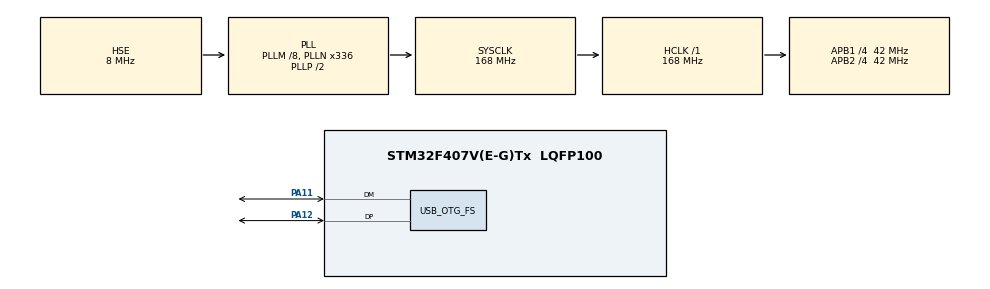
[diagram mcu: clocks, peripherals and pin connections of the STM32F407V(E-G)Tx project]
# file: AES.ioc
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Mcu.Family=STM32F4
Mcu.Name=STM32F407V(E-G)Tx
Mcu.Package=LQFP100
NVIC.OTG_FS_IRQn=true\:0\:0\:false\:false\:true
NVIC.PriorityGroup=NVIC_PRIORITYGROUP_4
PA11.Mode=Device_Only
PA11.Signal=USB_OTG_FS_DM
PA12.Mode=Device_Only
PA12.Signal=USB_OTG_FS_DP
PH0-OSC_IN.Mode=HSE-External-Oscillator
PH0-OSC_IN.Signal=RCC_OSC_IN
PH1-OSC_OUT.Mode=HSE-External-Oscillator
PH1-OSC_OUT.Signal=RCC_OSC_OUT
ProjectManager.HeapSize=0x200
ProjectManager.StackSize=0x400
ProjectManager.TargetToolchain=MDK-ARM V5
RCC.48MHZClocksFreq_Value=48000000
RCC.AHBFreq_Value=168000000
RCC.APB1CLKDivider=RCC_HCLK_DIV4
RCC.APB1Freq_Value=42000000
RCC.APB1TimFreq_Value=84000000
RCC.APB2CLKDivider=RCC_HCLK_DIV4
RCC.APB2Freq_Value=42000000
RCC.APB2TimFreq_Value=84000000
RCC.CortexFreq_Value=168000000
RCC.HCLKFreq_Value=168000000
RCC.HSE_VALUE=8000000
RCC.HSI_VALUE=16000000
RCC.LSE_VALUE=32768
RCC.PLLM=8
RCC.PLLN=336
RCC.PLLQ=7
RCC.SYSCLKFreq_VALUE=168000000
RCC.SYSCLKSource=RCC_SYSCLKSOURCE_PLLCLK
RCC.VCOOutputFreq_Value=336000000
USB_DEVICE.CLASS_NAME-CDC_FS=CDC
USB_DEVICE.CLASS_NAME_FS=CDC
USB_DEVICE.USBD_HandleTypeDef-CDC_FS=hUsbDeviceFS
USB_DEVICE.VirtualMode-CDC_FS=Cdc
USB_DEVICE.VirtualModeFS=Cdc_FS
USB_OTG_FS.VirtualMode=Device_Only
VP_USB_DEVICE_VS_USB_DEVICE_CDC_FS.Mode=CDC_FS
board=AES

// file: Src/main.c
/**
  ******************************************************************************
  * File Name          : main.c
  * Description        : Main program body
  ******************************************************************************
  *
  * COPYRIGHT(c) 2016 STMicroelectronics
  *
  * Redistribution and use in source and binary forms, with or without modification,
  * are permitted provided that the following conditions are met:
  *   1. Redistributions of source code must retain the above copyright notice,
  *      this list of conditions and the following disclaimer.
  *   2. Redistributions in binary form must reproduce the above copyright notice,
  *      this list of conditions and the following disclaimer in the documentation
  *      and/or other materials provided with the distribution.
  *   3. Neither the name of STMicroelectronics nor the names of its contributors
  *      may be used to endorse or promote products derived from this software
  *      without specific prior written permission.
  *
  * THIS SOFTWARE IS PROVIDED BY THE COPYRIGHT HOLDERS AND CONTRIBUTORS "AS IS"
  * AND ANY EXPRESS OR IMPLIED WARRANTIES, INCLUDING, BUT NOT LIMITED TO, THE
  * IMPLIED WARRANTIES OF MERCHANTABILITY AND FITNESS FOR A PARTICULAR PURPOSE ARE
  * DISCLAIMED. IN NO EVENT SHALL THE COPYRIGHT HOLDER OR CONTRIBUTORS BE LIABLE
  * FOR ANY DIRECT, INDIRECT, INCIDENTAL, SPECIAL, EXEMPLARY, OR CONSEQUENTIAL
  * DAMAGES (INCLUDING, BUT NOT LIMITED TO, PROCUREMENT OF SUBSTITUTE GOODS OR
  * SERVICES; LOSS OF USE, DATA, OR PROFITS; OR BUSINESS INTERRUPTION) HOWEVER
  * CAUSED AND ON ANY THEORY OF LIABILITY, WHETHER IN CONTRACT, STRICT LIABILITY,
  * OR TORT (INCLUDING NEGLIGENCE OR OTHERWISE) ARISING IN ANY WAY OUT OF THE USE
  * OF THIS SOFTWARE, EVEN IF ADVISED OF THE POSSIBILITY OF SUCH DAMAGE.
  *
  ******************************************************************************
  */
#include "stm32f4xx_hal.h"
#include "usb_device.h"

/* USER CODE BEGIN Includes */
#include "AES.h"
#include "usbd_cdc_if.h"

/* Mo ta hoat dong:
 * PC se gui xuong 17 byte, trong do byte dau tien chon che do
 * Neu byte dau tien = 0x11 thi chon mode ma hoa
 *                   = 0x22 thi chon mode giai ma
 * Tiep theo byte dau tien se la 16 byte du lieu
 * Tuy thuoc vao che do ma stm32f407 se dung 16 byte du lieu nay
 * de ma hoa hoac giai ma.
 * Sau do stm32 se gui len 17 byte. Trong do byte dau tien giong
 * byte ma may tinh gui xuong. 16 byte sau la du lieu da duoc ma hoa
 * hoac giai ma.
 */

/* USER CODE END Includes */

/* USER CODE BEGIN PV */
/* Private variables ---------------------------------------------------------*/
    AesCtx ctx;
    unsigned char i;
    unsigned char iv[] = "INI VECTINI VECT";
    unsigned char key[] = {0x00  ,0x01  ,0x02  ,0x03  ,0x04  ,0x05  ,0x06  ,0x07  ,0x08  ,0x09  ,0x0a  ,0x0b  ,0x0c  ,0x0d  ,0x0e  ,0x0f};
    unsigned char databuf[16]; // must be in multiple of 16
		unsigned char encryptbuf[16],decryptbuf[16];
    uint8_t _index=0;
		uint8_t receive_data[17];
		uint8_t send_data[17];
		uint8_t encrypt_flag=0,decrypt_flag=0;
/* USER CODE END PV */

void SystemClock_Config(void);
void Error_Handler(void);
static void MX_GPIO_Init(void);

/* USER CODE BEGIN PFP */
/* Private function prototypes -----------------------------------------------*/
void usb_cdc_isr(uint8_t * Buf);
/* USER CODE END PFP */

int main(void)
{

  /* MCU Configuration----------------------------------------------------------*/

  /* Reset of all peripherals, Initializes the Flash interface and the Systick. */
  HAL_Init();

  /* Configure the system clock */
  SystemClock_Config();

  /* Initialize all configured peripherals */
  MX_GPIO_Init();
  MX_USB_DEVICE_Init();

  /* USER CODE BEGIN 2 */

	/* Init AES */
  while (AesCtxIni(&ctx, iv, key, KEY128, EBC) < 0)
	{
	};

  /* USER CODE END 2 */

  /* Infinite loop */
  while (1)
  {

  /* USER CODE BEGIN 3 */
   if(encrypt_flag)
	 {
		 encrypt_flag=0;
		 /* Encrypt data */
		while (AesEncrypt(&ctx, databuf, encryptbuf, sizeof databuf) < 0)
		{
		};
		send_data[0]=receive_data[0];
		for(uint8_t i=0;i<16;i++)
		{
			send_data[i+1]=encryptbuf[i];
		}
		while(CDC_Transmit_FS(send_data,17)!=USBD_OK);
	 }
	 else if(decrypt_flag)
	 {
		 decrypt_flag=0;
		 	/* Decrypt data */
		while (AesDecrypt(&ctx, databuf, decryptbuf, sizeof databuf) < 0)
		{
		};
		send_data[0]=receive_data[0];
		for(uint8_t i=0;i<16;i++)
		{
			send_data[i+1]=decryptbuf[i];
		}
		while(CDC_Transmit_FS(send_data,17)!=USBD_OK);
	 }
  }
  /* USER CODE END 3 */

}

/** System Clock Configuration
*/
void SystemClock_Config(void)
{

  RCC_OscInitTypeDef RCC_OscInitStruct;
  RCC_ClkInitTypeDef RCC_ClkInitStruct;

  __HAL_RCC_PWR_CLK_ENABLE();

  __HAL_PWR_VOLTAGESCALING_CONFIG(PWR_REGULATOR_VOLTAGE_SCALE1);

  RCC_OscInitStruct.OscillatorType = RCC_OSCILLATORTYPE_HSE;
  RCC_OscInitStruct.HSEState = RCC_HSE_ON;
  RCC_OscInitStruct.PLL.PLLState = RCC_PLL_ON;
  RCC_OscInitStruct.PLL.PLLSource = RCC_PLLSOURCE_HSE;
  RCC_OscInitStruct.PLL.PLLM = 8;
  RCC_OscInitStruct.PLL.PLLN = 336;
  RCC_OscInitStruct.PLL.PLLP = RCC_PLLP_DIV2;
  RCC_OscInitStruct.PLL.PLLQ = 7;
  if (HAL_RCC_OscConfig(&RCC_OscInitStruct) != HAL_OK)
  {
    Error_Handler();
  }

  RCC_ClkInitStruct.ClockType = RCC_CLOCKTYPE_HCLK|RCC_CLOCKTYPE_SYSCLK
                              |RCC_CLOCKTYPE_PCLK1|RCC_CLOCKTYPE_PCLK2;
  RCC_ClkInitStruct.SYSCLKSource = RCC_SYSCLKSOURCE_PLLCLK;
  RCC_ClkInitStruct.AHBCLKDivider = RCC_SYSCLK_DIV1;
  RCC_ClkInitStruct.APB1CLKDivider = RCC_HCLK_DIV4;
  RCC_ClkInitStruct.APB2CLKDivider = RCC_HCLK_DIV4;
  if (HAL_RCC_ClockConfig(&RCC_ClkInitStruct, FLASH_LATENCY_5) != HAL_OK)
  {
    Error_Handler();
  }

  HAL_SYSTICK_Config(HAL_RCC_GetHCLKFreq()/1000);

  HAL_SYSTICK_CLKSourceConfig(SYSTICK_CLKSOURCE_HCLK);

  /* SysTick_IRQn interrupt configuration */
  HAL_NVIC_SetPriority(SysTick_IRQn, 0, 0);
}

/** Configure pins as
        * Analog
        * Input
        * Output
        * EVENT_OUT
        * EXTI
*/
static void MX_GPIO_Init(void)
{

  /* GPIO Ports Clock Enable */
  __HAL_RCC_GPIOH_CLK_ENABLE();
  __HAL_RCC_GPIOA_CLK_ENABLE();

}

/* USER CODE BEGIN 4 */
void usb_cdc_isr(uint8_t * Buf)
{
	receive_data[_index]=Buf[0];
	if(++_index==17)
	{
		_index=0;

		for(uint8_t i=0;i<16;i++)
		{
			databuf[i]=receive_data[i+1];
		}

		if(receive_data[0]==0x11) //ma hoa
		{
			encrypt_flag=1;
		}
		else if (receive_data[0]==0x22) //giai ma
		{
			decrypt_flag=1;
		}
	}
}
/* USER CODE END 4 */

void Error_Handler(void)
{
  while(1)
  {
  }
}

/************************ (C) COPYRIGHT STMicroelectronics *****END OF FILE****/
